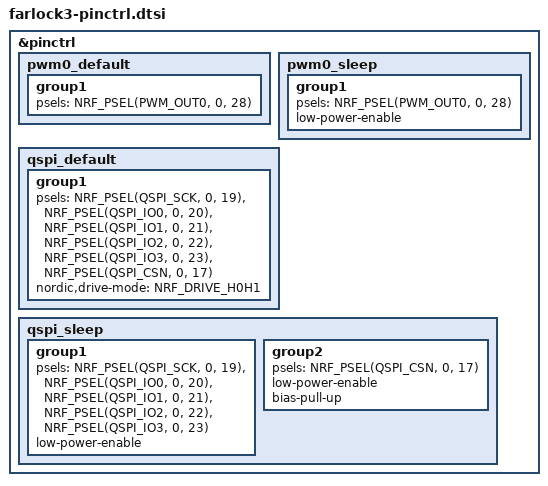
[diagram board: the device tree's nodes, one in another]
/*
 * FARLock v3 pin control. Only peripherals that are actually routed on the
 * v02 PCB are described here.
 *
 * SPDX-License-Identifier: Apache-2.0
 */

&pinctrl {
	/* TB6612FNG PWMA */
	pwm0_default: pwm0_default {
		group1 {
			psels = <NRF_PSEL(PWM_OUT0, 0, 28)>;
		};
	};

	pwm0_sleep: pwm0_sleep {
		group1 {
			psels = <NRF_PSEL(PWM_OUT0, 0, 28)>;
			low-power-enable;
		};
	};

	/* MX25R6435F */
	qspi_default: qspi_default {
		group1 {
			psels = <NRF_PSEL(QSPI_SCK, 0, 19)>,
				<NRF_PSEL(QSPI_IO0, 0, 20)>,
				<NRF_PSEL(QSPI_IO1, 0, 21)>,
				<NRF_PSEL(QSPI_IO2, 0, 22)>,
				<NRF_PSEL(QSPI_IO3, 0, 23)>,
				<NRF_PSEL(QSPI_CSN, 0, 17)>;
			nordic,drive-mode = <NRF_DRIVE_H0H1>;
		};
	};

	qspi_sleep: qspi_sleep {
		group1 {
			psels = <NRF_PSEL(QSPI_SCK, 0, 19)>,
				<NRF_PSEL(QSPI_IO0, 0, 20)>,
				<NRF_PSEL(QSPI_IO1, 0, 21)>,
				<NRF_PSEL(QSPI_IO2, 0, 22)>,
				<NRF_PSEL(QSPI_IO3, 0, 23)>;
			low-power-enable;
		};

		group2 {
			psels = <NRF_PSEL(QSPI_CSN, 0, 17)>;
			low-power-enable;
			bias-pull-up;
		};
	};
};
